VERSION ""

NS_ :

BS_:

BU_: Display PERS PCU_LMX MIC_id10 MIC_id20 Battery
VAL_TABLE_ VESC_Fault_Code 29 "LV_OUTPUT_FAULT" 28 "ENCODER_FAULT" 27 "PHASE_FILTER" 26 "ENCODER_MAGNET_TOO_STRONG" 25 "ENCODER_NO_MAGNET" 24 "FLASH_CORRUPTION_MC_CFG" 23 "FLASH_CORRUPTION_APP_CFG" 22 "RESOLVER_LOS" 21 "RESOLVER_DOS" 20 "RESOLVER_LOT" 19 "BRK" 18 "UNBALANCED_CURRENTS" 17 "HIGH_OFFSET_CURRENT_SENSOR_3" 16 "HIGH_OFFSET_CURRENT_SENSOR_2" 15 "HIGH_OFFSET_CURRENT_SENSOR_1" 14 "FLASH_CORRUPTION" 13 "ENCODER_SINCOS_MAX_AMPLITUDE" 12 "ENCODER_SINCOS_MIN_AMPLITUDE" 11 "ENCODER_SPI" 10 "BOOTING_FROM_WATCHDOG_RESET" 9 "MCU_UNDER_VOLTAGE" 8 "GATE_DRIVER_UNDER_VOLTAGE" 7 "GATE_DRIVER_OVER_VOLTAGE" 6 "OVER_TEMP_MOTOR" 5 "OVER_TEMP_FET" 4 "ABS_OVER_CURRENT" 3 "DRV" 2 "UNDER_VOLTAGE" 1 "OVER_VOLTAGE" 0 "NONE" ;
VAL_TABLE_ BMS_State 120 "REGEN" 110 "DISCHARGING" 100 "IDLE" 90 "OVERVOLTAGE" 70 "STANDBY" 40 "UNDERVOLTAGE" 30 "PROTECT" 20 "INIT" 10 "ERROR" ;

BO_ 3221225472 VECTOR__INDEPENDENT_SIG_MSG: 0 Vector__XXX
 SG_ Set_DutyCycle : 0|16@0- (1E-05,0) [-1|1] "%/100" Vector__XXX
 SG_ Set_DutyCycle : 0|16@0- (1E-05,0) [-1|1] "%/100" Vector__XXX

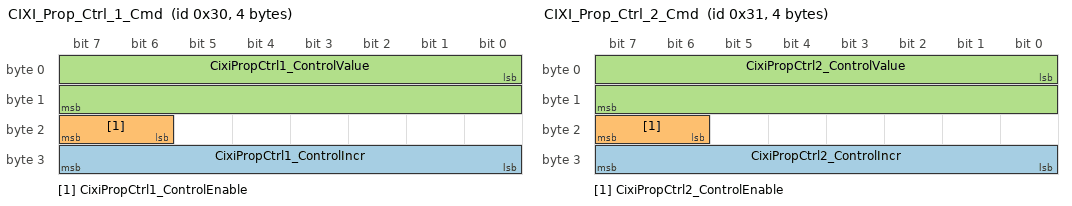
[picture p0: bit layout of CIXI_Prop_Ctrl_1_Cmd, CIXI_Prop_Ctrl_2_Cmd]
BO_ 48 CIXI_Prop_Ctrl_1_Cmd: 4 PERS
 SG_ CixiPropCtrl1_ControlIncr : 24|8@1+ (1,0) [0|255] "-"  PCU_LMX
 SG_ CixiPropCtrl1_ControlEnable : 22|2@1+ (1,0) [0|3] ""  PCU_LMX
 SG_ CixiPropCtrl1_ControlValue : 0|16@1- (0.1,0) [-3276|3276] "N.m"  PCU_LMX

BO_ 49 CIXI_Prop_Ctrl_2_Cmd: 4 PERS
 SG_ CixiPropCtrl2_ControlIncr : 24|8@1+ (1,0) [0|255] "-"  PCU_LMX
 SG_ CixiPropCtrl2_ControlEnable : 22|2@1+ (1,0) [0|3] ""  PCU_LMX
 SG_ CixiPropCtrl2_ControlValue : 0|16@1- (0.1,0) [-3276|3276] "N.m"  PCU_LMX

BO_ 56 CIXI_Prop_Ctrl_1_Status: 7 PCU_LMX
 SG_ CixiPropCtrl1_Iq m2 : 40|16@1- (0.01,0) [-327|327] "A"  PERS
 SG_ CixiPropCtrl1_MotorRpmSensless m1 : 40|16@1- (0.1,0) [-3276|3276] "RPM"  PERS
 SG_ CixiPropCtrl1_MotorRpmSensored m0 : 40|16@1- (0.1,0) [-3276|3276] "RPM"  PERS
 SG_ CixiPropCtrl1_InputCurrent m2 : 24|16@1- (0.01,0) [-327|327] "A"  PERS
 SG_ CixiPropCtrl1_MechanicalPower m1 : 24|16@1- (1,0) [-32768|32767] "W"  PERS
 SG_ CixiPropCtrl1_MotorTorque m0 : 24|16@1- (0.1,0) [-3276|3276] "N.m"  PERS
 SG_ CixiPropCtrl1_InputVoltage m2 : 8|16@1+ (0.01,0) [0|655] "V"  PERS
 SG_ CixiPropCtrl1_ElectricalPower m1 : 8|16@1- (1,0) [-32768|32767] "W"  PERS
 SG_ CixiPropCtrl1_ControlValueIn m0 : 8|16@1- (0.1,0) [-3276|3276] "N.m"  PERS
 SG_ CixiPropCtrl1_ControlState : 6|2@1+ (1,0) [0|3] ""  PERS
 SG_ CixiPropCtrl1_StatusNbPage : 2|2@1+ (1,0) [0|3] ""  PERS
 SG_ CixiPropCtrl1_StatusPage M : 0|2@1+ (1,0) [0|3] ""  PERS

BO_ 57 CIXI_Prop_Ctrl_2_Status: 7 PCU_LMX
 SG_ CixiPropCtrl2_Iq m2 : 40|16@1- (0.01,0) [-327|327] "A"  PERS
 SG_ CixiPropCtrl2_MotorRpmSensless m1 : 40|16@1- (0.1,0) [-3276|3276] "RPM"  PERS
 SG_ CixiPropCtrl2_MotorRpmSensored m0 : 40|16@1- (0.1,0) [-3276|3276] "RPM"  PERS
 SG_ CixiPropCtrl2_InputCurrent m2 : 24|16@1- (0.01,0) [-327|327] "A"  PERS
 SG_ CixiPropCtrl2_MechanicalPower m1 : 24|16@1- (1,0) [-32768|32767] "W"  PERS
 SG_ CixiPropCtrl2_MotorTorque m0 : 24|16@1- (0.1,0) [-3276|3276] "N.m"  PERS
 SG_ CixiPropCtrl2_InputVoltage m2 : 8|16@1+ (0.01,0) [0|655] "V"  PERS
 SG_ CixiPropCtrl2_ElectricalPower m1 : 8|16@1- (1,0) [-32768|32767] "W"  PERS
 SG_ CixiPropCtrl2_ControlValueIn m0 : 8|16@1- (0.1,0) [-3276|3276] "N.m"  PERS
 SG_ CixiPropCtrl2_ControlState : 6|2@1+ (1,0) [0|3] ""  PERS
 SG_ CixiPropCtrl2_StatusNbPage : 2|2@1+ (1,0) [0|3] ""  PERS
 SG_ CixiPropCtrl2_StatusPage M : 0|2@1+ (1,0) [0|3] ""  PERS

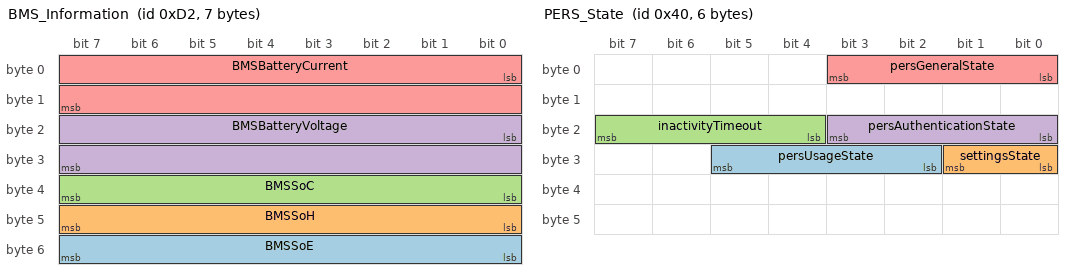
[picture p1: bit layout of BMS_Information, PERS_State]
BO_ 210 BMS_Information: 7 PCU_LMX
 SG_ BMSSoE : 48|8@1- (1,0) [0|100] "%"  PERS
 SG_ BMSSoH : 40|8@1- (1,0) [0|100] "%"  PERS
 SG_ BMSSoC : 32|8@1- (1,0) [0|100] "%"  PERS
 SG_ BMSBatteryVoltage : 16|16@1- (0.01,0) [0|655] "V"  PERS
 SG_ BMSBatteryCurrent : 0|16@1- (0.01,0) [-327|327] "A"  PERS

BO_ 64 PERS_State: 6 PERS
 SG_ persUsageState : 26|4@1+ (1,0) [0|15] "-" Vector__XXX
 SG_ settingsState : 24|2@1+ (1,0) [0|3] "-" Vector__XXX
 SG_ inactivityTimeout : 20|4@1+ (1,0) [0|15] "sec" Vector__XXX
 SG_ persAuthenticationState : 16|4@1+ (1,0) [0|15] "" Vector__XXX
 SG_ persGeneralState : 0|4@1+ (1,0) [0|15] "" Vector__XXX

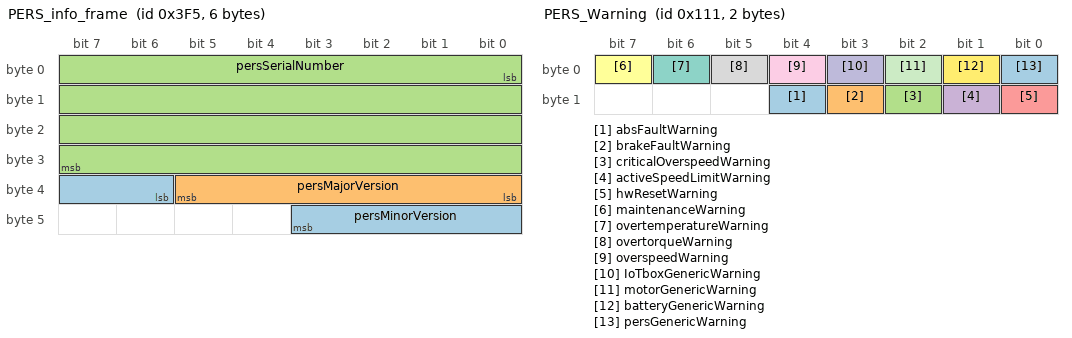
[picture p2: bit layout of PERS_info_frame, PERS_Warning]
BO_ 1013 PERS_info_frame: 6 PERS
 SG_ persMinorVersion : 38|6@1+ (1,0) [0|63] "-" Vector__XXX
 SG_ persMajorVersion : 32|6@1+ (1,0) [0|63] "-" Vector__XXX
 SG_ persSerialNumber : 0|32@1+ (1,0) [0|4294967295] "-" Vector__XXX

BO_ 273 PERS_Warning: 2 PERS
 SG_ absFaultWarning : 12|1@1+ (1,0) [0|1] "-" Vector__XXX
 SG_ brakeFaultWarning : 11|1@1+ (1,0) [0|1] "-" Vector__XXX
 SG_ criticalOverspeedWarning : 10|1@1+ (1,0) [0|1] "-" Vector__XXX
 SG_ activeSpeedLimitWarning : 9|1@1+ (1,0) [0|1] "-" Vector__XXX
 SG_ hwResetWarning : 8|1@1+ (1,0) [0|1] "-" Vector__XXX
 SG_ maintenanceWarning : 7|1@1+ (1,0) [0|1] "-" Vector__XXX
 SG_ overtemperatureWarning : 6|1@1+ (1,0) [0|1] "-" Vector__XXX
 SG_ overtorqueWarning : 5|1@1+ (1,0) [0|1] "" Vector__XXX
 SG_ overspeedWarning : 4|1@1+ (1,0) [0|1] "-" Vector__XXX
 SG_ IoTboxGenericWarning : 3|1@1+ (1,0) [0|1] "-" Vector__XXX
 SG_ motorGenericWarning : 2|1@1+ (1,0) [0|1] "-" Vector__XXX
 SG_ batteryGenericWarning : 1|1@1+ (1,0) [0|1] "-" Vector__XXX
 SG_ persGenericWarning : 0|1@1+ (1,0) [0|1] "-" Vector__XXX

BO_ 272 PERS_Error: 1 PERS
 SG_ persGenericError : 0|1@1+ (1,0) [0|1] "-" Vector__XXX

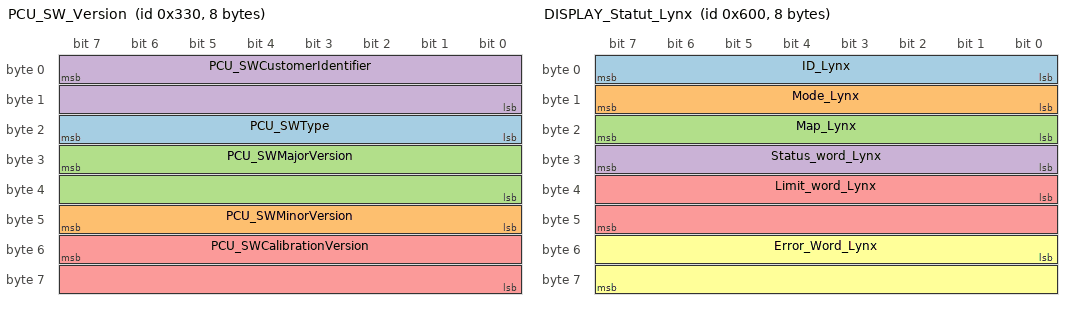
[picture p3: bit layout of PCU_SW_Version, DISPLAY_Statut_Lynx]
BO_ 816 PCU_SW_Version: 8 PCU_LMX
 SG_ PCU_SWType : 23|8@0+ (1,0) [0|0] "" Vector__XXX
 SG_ PCU_SWMinorVersion : 47|8@0+ (1,0) [0|0] "" Vector__XXX
 SG_ PCU_SWMajorVersion : 31|16@0+ (1,0) [0|0] "" Vector__XXX
 SG_ PCU_SWCustomerIdentifier : 7|16@0+ (1,0) [0|0] "" Vector__XXX
 SG_ PCU_SWCalibrationVersion : 55|16@0+ (1,0) [0|0] "" Vector__XXX

BO_ 1536 DISPLAY_Statut_Lynx: 8 PCU_LMX
 SG_ ID_Lynx : 0|8@1+ (1,0) [0|0] ""  Display
 SG_ Mode_Lynx : 8|8@1+ (1,0) [0|0] ""  Display
 SG_ Map_Lynx : 16|8@1+ (1,0) [0|0] ""  Display
 SG_ Status_word_Lynx : 24|8@1+ (1,0) [0|0] ""  Display
 SG_ Limit_word_Lynx : 32|16@1+ (1,0) [0|0] ""  Display
 SG_ Error_Word_Lynx : 48|16@1+ (1,0) [0|0] ""  Display

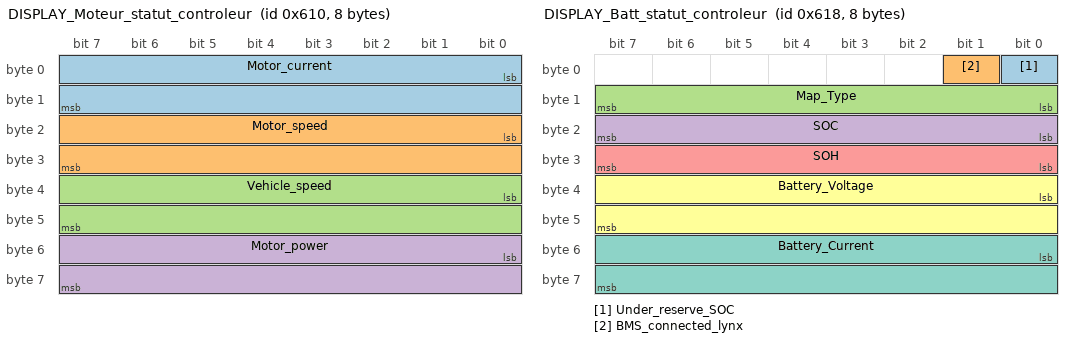
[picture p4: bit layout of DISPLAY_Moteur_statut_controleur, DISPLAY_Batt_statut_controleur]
BO_ 1552 DISPLAY_Moteur_statut_controleur: 8 PCU_LMX
 SG_ Motor_current : 0|16@1- (1,0) [-32768|32767] "A"  Display
 SG_ Motor_speed : 16|16@1- (1,0) [-32768|32767] "RPM"  Display
 SG_ Vehicle_speed : 32|16@1- (0.01,0) [0|0] "km/h"  Display
 SG_ Motor_power : 48|16@1- (1,0) [0|0] "W"  Display

BO_ 1560 DISPLAY_Batt_statut_controleur: 8 PCU_LMX
 SG_ Under_reserve_SOC : 0|1@1+ (1,0) [0|0] ""  Display
 SG_ BMS_connected_lynx : 1|1@1+ (1,0) [0|0] ""  Display
 SG_ Map_Type : 8|8@1+ (1,0) [0|0] ""  Display
 SG_ SOC : 16|8@1+ (1,0) [0|100] "%"  Display
 SG_ SOH : 24|8@1+ (1,0) [0|0] "%"  Display
 SG_ Battery_Voltage : 32|16@1- (0.01,0) [-327.68|327.67] "V"  Display
 SG_ Battery_Current : 48|16@1- (0.02,0) [-655.36|655.34] "A"  Display

BO_ 1568 DISPLAY_Odo_trip_controleur: 8 PCU_LMX
 SG_ Trip : 0|32@1+ (0.01,0) [0|0] "km"  Display
 SG_ Odometer : 32|32@1+ (0.1,0) [0|0] "km"  Display

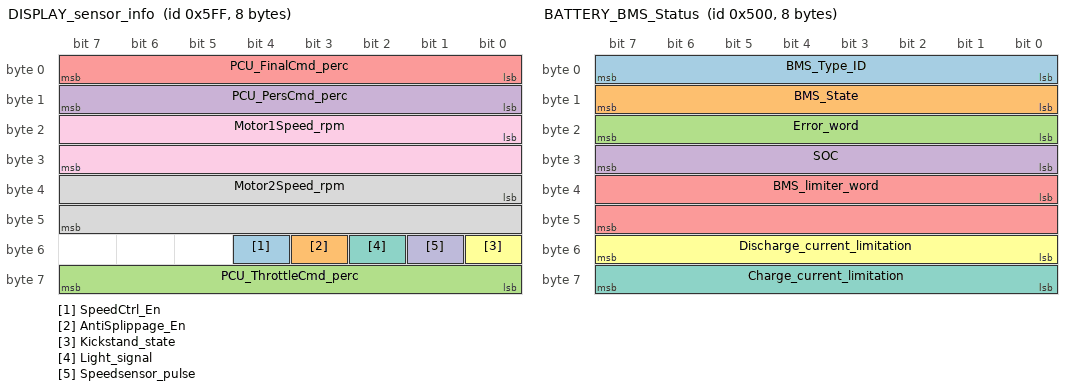
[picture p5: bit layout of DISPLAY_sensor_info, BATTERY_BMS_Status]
BO_ 1535 DISPLAY_sensor_info: 8 PCU_LMX
 SG_ SpeedCtrl_En : 52|1@1- (1,0) [0|0] "" Vector__XXX
 SG_ AntiSplippage_En : 51|1@1- (1,0) [0|0] "" Vector__XXX
 SG_ PCU_ThrottleCmd_perc : 56|8@1+ (1,-100) [-100|100] "%" Vector__XXX
 SG_ PCU_PersCmd_perc : 8|8@1+ (1,-100) [-100|100] "%" Vector__XXX
 SG_ PCU_FinalCmd_perc : 0|8@1+ (1,-100) [-100|100] "%" Vector__XXX
 SG_ Kickstand_state : 48|1@1+ (1,0) [0|0] "" Vector__XXX
 SG_ Light_signal : 50|1@1+ (1,0) [0|0] "" Vector__XXX
 SG_ Motor2Speed_rpm : 32|16@1- (1,0) [-32768|32767] "RPM" Vector__XXX
 SG_ Motor1Speed_rpm : 16|16@1- (1,0) [-32768|32767] "RPM" Vector__XXX
 SG_ Speedsensor_pulse : 49|1@1+ (1,0) [0|0] ""  Display

BO_ 1280 BATTERY_BMS_Status: 8 Battery
 SG_ BMS_Type_ID : 0|8@1+ (1,0) [-3276.8|3276.7] ""  PCU_LMX
 SG_ BMS_State : 8|8@1+ (1,0) [-3276.8|3276.7] ""  PCU_LMX
 SG_ Error_word : 16|8@1+ (0.1,0) [-3276.8|3276.7] ""  PCU_LMX
 SG_ SOC : 24|8@1+ (0.5,0) [0|200] "%"  PCU_LMX
 SG_ BMS_limiter_word : 32|16@1+ (1,0) [-32768|32767] ""  PCU_LMX
 SG_ Discharge_current_limitation : 48|8@1+ (1,0) [0|255] "%"  PCU_LMX
 SG_ Charge_current_limitation : 56|8@1+ (1,0) [0|255] "%"  PCU_LMX

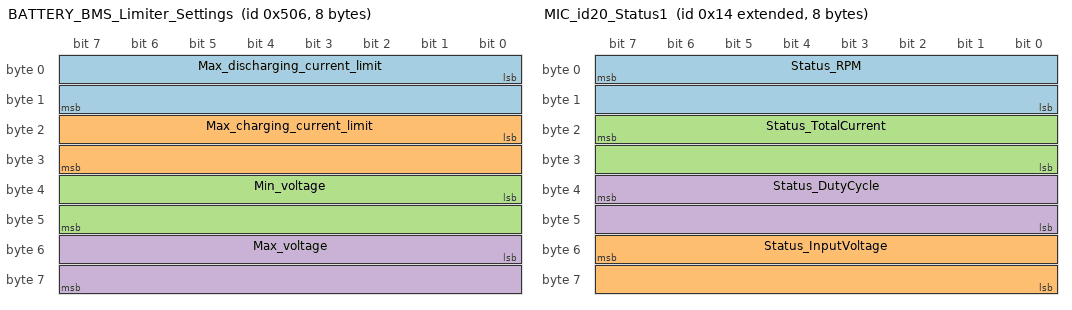
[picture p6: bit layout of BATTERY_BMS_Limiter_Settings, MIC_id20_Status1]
BO_ 1286 BATTERY_BMS_Limiter_Settings: 8 Battery
 SG_ Max_discharging_current_limit : 0|16@1- (0.1,0) [-3276.8|3276.7] "A"  PCU_LMX
 SG_ Max_charging_current_limit : 16|16@1- (0.1,0) [-3276.8|3276.7] "A"  PCU_LMX
 SG_ Min_voltage : 32|16@1- (0.1,0) [-3276.8|3276.7] "V"  PCU_LMX
 SG_ Max_voltage : 48|16@1- (0.1,0) [-3276.8|3276.7] "V"  PCU_LMX

BO_ 2147489556 MIC_id20_Set_InputCurrent_Limits: 8 PCU_LMX
 SG_ Set_Min_Input_Current_Limit : 7|32@0- (0.001,0) [-2147483.648|0] "A"  MIC_id20
 SG_ Set_Max_Input_Current_Limit : 39|32@0- (0.001,0) [0|2147483.647] "A"  MIC_id20

BO_ 2147489546 MIC_id10_Set_InputCurrent_Limits: 8 PCU_LMX
 SG_ Set_Min_Input_Current_Limit : 7|32@0- (0.001,0) [-2147483.648|0] "A"  MIC_id20
 SG_ Set_Max_Input_Current_Limit : 39|32@0- (0.001,0) [0|2147483.647] "A"  MIC_id20

BO_ 2147489044 MIC_id20_Set_Current_Limits: 8 PCU_LMX
 SG_ Set_Min_Current_Limit : 7|32@0- (0.001,0) [-2147483.648|0] "Arms"  MIC_id20
 SG_ Set_Max_Current_Limit : 39|32@0- (0.001,0) [0|2147483.647] "Arms"  MIC_id20

BO_ 2147489034 MIC_id10_Set_Current_Limits: 8 PCU_LMX
 SG_ Set_Min_Current_Limit : 7|32@0- (0.001,0) [-2147483.648|0] "Arms"  MIC_id20
 SG_ Set_Max_Current_Limit : 39|32@0- (0.001,0) [0|2147483.647] "Arms"  MIC_id20

BO_ 2147484180 MIC_id20_Set_Current_Brake: 4 PCU_LMX
 SG_ Set_Current_Brake : 7|32@0- (0.001,0) [-2147483.648|2147483.647] "Arms"  MIC_id20

BO_ 2147484170 MIC_id10_Set_Current_Brake: 4 PCU_LMX
 SG_ Set_Current_Brake : 7|32@0- (0.001,0) [-2147483.648|2147483.647] "Arms"  MIC_id20

BO_ 2147483924 MIC_id20_Set_Current: 4 PCU_LMX
 SG_ Set_Current : 7|32@0- (0.001,0) [-2147483.648|2147483.647] "Arms"  MIC_id20

BO_ 2147483914 MIC_id10_Set_Current: 4 PCU_LMX
 SG_ Set_Current : 7|32@0- (0.001,0) [-2147483.648|2147483.647] "Arms"  MIC_id20

BO_ 2147485706 MIC_id10_Send_Command: 7 PCU_LMX
 SG_ Value : 31|32@0- (0.001,0) [-32768|32767] ""  MIC_id20
 SG_ mode : 23|8@0+ (1,0) [0|0] ""  MIC_id20

BO_ 2147485716 MIC_id20_Send_Command: 7 PCU_LMX
 SG_ mode : 23|8@0+ (1,0) [0|0] ""  MIC_id20,MIC_id10
 SG_ Value : 31|32@0- (0.001,0) [-32768|32767] ""  MIC_id20,MIC_id10

BO_ 2147483668 MIC_id20_Status1: 8 MIC_id20
 SG_ Status_RPM : 7|16@0- (2,0) [-6553.6|6553.4] "RPM" Vector__XXX
 SG_ Status_InputVoltage : 55|16@0- (0.1,0) [-3276.8|3276.7] "V" Vector__XXX
 SG_ Status_TotalCurrent : 23|16@0- (0.1,0) [-3276.8|3276.7] "ARMS"  PCU_LMX
 SG_ Status_DutyCycle : 39|16@0- (0.1,0) [-100|100] "%"  PCU_LMX

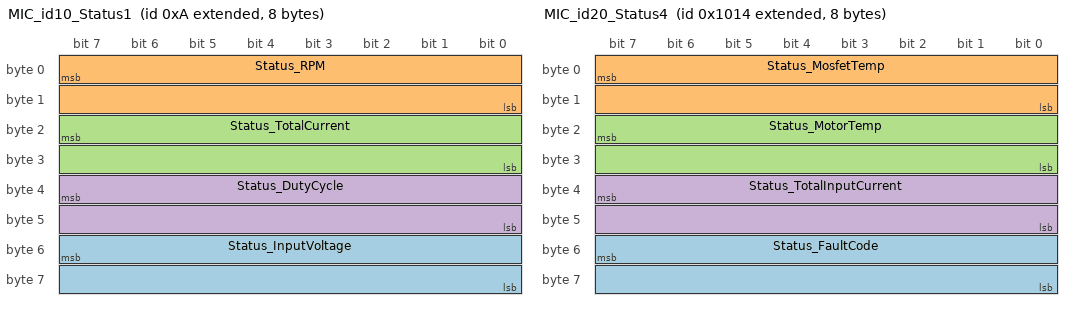
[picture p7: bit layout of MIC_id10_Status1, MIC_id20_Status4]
BO_ 2147483658 MIC_id10_Status1: 8 MIC_id10
 SG_ Status_InputVoltage : 55|16@0- (0.1,0) [-3276.8|3276.7] "V" Vector__XXX
 SG_ Status_RPM : 7|16@0- (2,0) [-6553.6|6553.4] "RPM"  PCU_LMX
 SG_ Status_TotalCurrent : 23|16@0- (0.1,0) [-327.68|327.67] "ARMS"  PCU_LMX
 SG_ Status_DutyCycle : 39|16@0- (0.1,0) [-3276.8|3276.7] "%"  PCU_LMX

BO_ 2147487252 MIC_id20_Status2: 8 MIC_id20
 SG_ Status_Iq : 39|32@0- (0.001,0) [-214748.3648|214748.3647] "A" Vector__XXX
 SG_ Status_Id : 7|32@0- (0.001,0) [-214748364.8|214748364.7] "A" Vector__XXX

BO_ 2147487242 MIC_id10_Status2: 8 MIC_id10
 SG_ Status_Id : 7|32@0- (0.001,0) [-21474836.48|21474836.47] "A"  PCU_LMX
 SG_ Status_Iq : 39|32@0- (0.001,0) [-2147483.648|2147483.647] "A"  PCU_LMX

BO_ 2147487508 MIC_id20_Status3: 8 MIC_id20
 SG_ Status_WattHoursCharged : 39|32@0- (1E-05,0) [-21474.83648|21474.83647] "Wh"  PCU_LMX
 SG_ Status_WattHours : 7|32@0- (1E-05,0) [-21474.83648|21474.83647] "Wh"  PCU_LMX

BO_ 2147487498 MIC_id10_Status3: 8 MIC_id10
 SG_ Status_WattHours : 7|32@0- (0.0001,0) [-21474.83648|21474.83647] "Wh"  PCU_LMX
 SG_ Status_WattHoursCharged : 39|32@0- (0.0001,0) [-21474.83648|21474.83647] "Wh"  PCU_LMX

BO_ 2147487764 MIC_id20_Status4: 8 MIC_id20
 SG_ Status_FaultCode : 55|16@0+ (1,0) [0|65535] "" Vector__XXX
 SG_ Status_MosfetTemp : 7|16@0- (0.1,0) [-3276.8|3276.7] "degC"  PCU_LMX
 SG_ Status_MotorTemp : 23|16@0- (0.1,0) [-3276.8|3276.7] "degC"  PCU_LMX
 SG_ Status_TotalInputCurrent : 39|16@0- (0.1,0) [-3276.8|3276.7] "A"  PCU_LMX

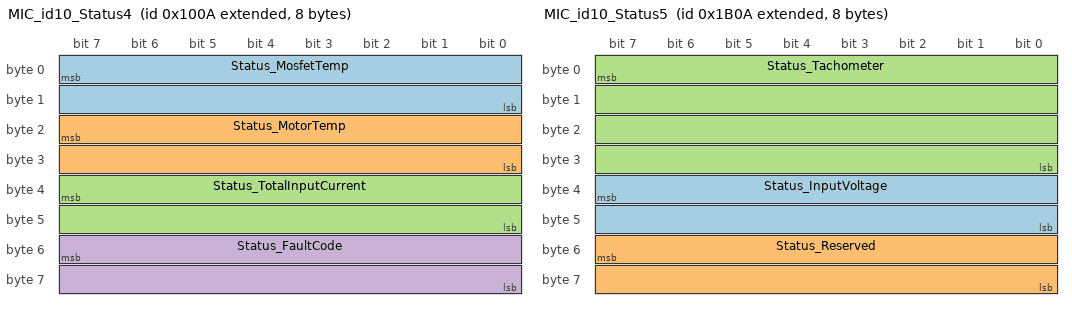
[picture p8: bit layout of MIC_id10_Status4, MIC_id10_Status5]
BO_ 2147487754 MIC_id10_Status4: 8 MIC_id10
 SG_ Status_MosfetTemp : 7|16@0- (0.1,0) [-3276.8|3276.7] "degC"  PCU_LMX
 SG_ Status_MotorTemp : 23|16@0- (0.1,0) [-3276.8|3276.7] "degC"  PCU_LMX
 SG_ Status_TotalInputCurrent : 39|16@0- (0.1,0) [-3276.8|3276.7] "A"  PCU_LMX
 SG_ Status_FaultCode : 55|16@0+ (1,0) [0|65535] ""  PCU_LMX

BO_ 2147490580 MIC_id20_Status5: 8 MIC_id20
 SG_ Status_Reserved : 55|16@0- (1,0) [0|0] ""  PCU_LMX
 SG_ Status_Tachometer : 7|32@0- (1,0) [0|0] "RPM"  PCU_LMX

BO_ 2147490570 MIC_id10_Status5: 8 MIC_id10
 SG_ Status_InputVoltage : 39|16@0- (0.1,0) [-3276.8|3276.7] "V"  PCU_LMX
 SG_ Status_Reserved : 55|16@0- (1,0) [0|0] ""  PCU_LMX
 SG_ Status_Tachometer : 7|32@0- (1,0) [0|0] "RPM"  PCU_LMX

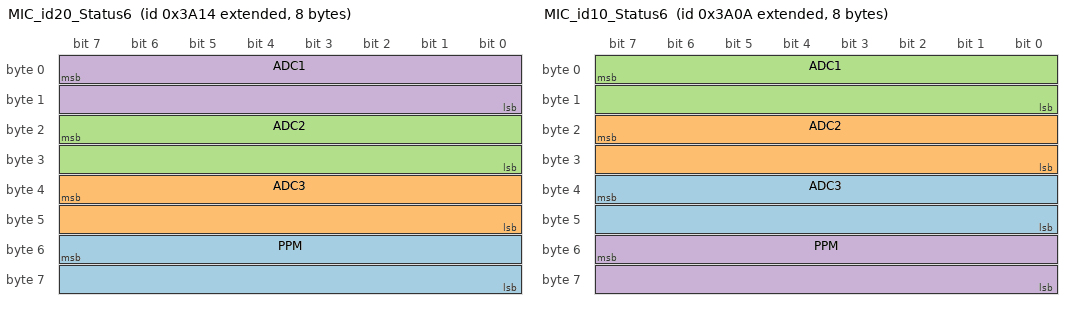
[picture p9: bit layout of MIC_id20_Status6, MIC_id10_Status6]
BO_ 2147498516 MIC_id20_Status6: 8 MIC_id20
 SG_ PPM : 55|16@0+ (1000,0) [0|0] "%"  PCU_LMX
 SG_ ADC3 : 39|16@0+ (0.001,0) [0|0] "V"  PCU_LMX
 SG_ ADC2 : 23|16@0+ (0.001,0) [0|0] "V"  PCU_LMX
 SG_ ADC1 : 7|16@0+ (0.001,0) [0|0] "V"  PCU_LMX

BO_ 2147498506 MIC_id10_Status6: 8 MIC_id10
 SG_ ADC3 : 39|16@0+ (0.001,0) [0|0] "V" Vector__XXX
 SG_ ADC2 : 23|16@0+ (0.001,0) [0|0] "V" Vector__XXX
 SG_ ADC1 : 7|16@0+ (0.001,0) [0|0] "V" Vector__XXX
 SG_ PPM : 55|16@0+ (1000,0) [0|0] "%"  PCU_LMX

CM_ BU_ PCU_LMX "
";
CM_ BO_ 3221225472 "This is a message for not used signals, created by Vector CANdb++ DBC OLE DB Provider.";
CM_ SG_ 48 CixiPropCtrl1_ControlIncr "Incremental value to be sure that command is not frozen.";
CM_ SG_ 48 CixiPropCtrl1_ControlEnable "The \"CixiPropCtrlControlValue\" shall be take into account only if ENABLE=3DACTIVE";
CM_ SG_ 48 CixiPropCtrl1_ControlValue "Torque setpoint to apply";
CM_ SG_ 49 CixiPropCtrl2_ControlIncr "Incremental value to be sure that command is not frozen.";
CM_ SG_ 49 CixiPropCtrl2_ControlEnable "The \"CixiPropCtrlControlValue\" shall be take into account only if ENABLE=3DACTIVE";
CM_ SG_ 49 CixiPropCtrl2_ControlValue "Torque setpoint to apply";
CM_ SG_ 210 BMSSoC "Battery state of Charge";
CM_ SG_ 273 criticalOverspeedWarning "vehicle critical overspeed warning";
CM_ SG_ 273 activeSpeedLimitWarning "Active speed limit unavailable";
CM_ SG_ 273 hwResetWarning "PERS HW reset trigger warning";
CM_ SG_ 273 maintenanceWarning "Mid-life maintenance warning";
CM_ SG_ 273 overtemperatureWarning "System is too hot";
CM_ SG_ 273 overspeedWarning "Vehicle overspeed warning";
CM_ BO_ 1536 "100 ms";
CM_ BO_ 1552 "100 ms";
CM_ BO_ 1560 "100 ms";
CM_ SG_ 1560 SOC "Battery Sate of Charge";
CM_ SG_ 1560 Battery_Voltage "Battery voltage";
CM_ SG_ 1560 Battery_Current "Battery current";
CM_ BO_ 1568 "100 ms";
CM_ BO_ 1535 "50 ms";
CM_ SG_ 1280 BMS_Type_ID "ID of the BMS type (expected 0xF0)";
CM_ SG_ 1280 BMS_State "BMS status";
CM_ SG_ 1280 Error_word "Not Used";
CM_ SG_ 1280 SOC "Battery State of Charge";
CM_ SG_ 1280 BMS_limiter_word "Not Used";
CM_ SG_ 1280 Discharge_current_limitation "Dynamic discharge derating
Max discharge current available (%) = round(RAW_Val * (255 /100))";
CM_ SG_ 1280 Charge_current_limitation "Dynamic regen derating
Max charge current available (%) = round(RAW_Val * (255 /100))";
BA_DEF_ BO_  "VFrameFormat" ENUM  "StandardCAN","ExtendedCAN","reserved","reserved","reserved","reserved","reserved","reserved","reserved","reserved","reserved","reserved","reserved","reserved","StandardCAN_FD","ExtendedCAN_FD";
BA_DEF_ BO_  "CANFD_BRS" ENUM  "0","1";
BA_DEF_  "BusType" STRING ;
BA_DEF_ SG_  "GenSigStartValue" FLOAT -3.4E+38 3.4E+38;
BA_DEF_DEF_  "VFrameFormat" "";
BA_DEF_DEF_  "CANFD_BRS" "1";
BA_DEF_DEF_  "BusType" "CAN";
BA_DEF_DEF_  "GenSigStartValue" 0;
BA_ "VFrameFormat" BO_ 56 0;
BA_ "VFrameFormat" BO_ 57 0;
BA_ "VFrameFormat" BO_ 210 0;
BA_ "VFrameFormat" BO_ 816 0;
BA_ "VFrameFormat" BO_ 1535 0;
BA_ "VFrameFormat" BO_ 2147483668 1;
BA_ "VFrameFormat" BO_ 2147483658 1;
BA_ "VFrameFormat" BO_ 2147487252 1;
BA_ "VFrameFormat" BO_ 2147487764 1;
BA_ "VFrameFormat" BO_ 2147498506 1;
BA_ "GenSigStartValue" SG_ 1535 PCU_ThrottleCmd_perc 100;
BA_ "GenSigStartValue" SG_ 1535 PCU_PersCmd_perc 100;
BA_ "GenSigStartValue" SG_ 1535 PCU_FinalCmd_perc 100;
VAL_ 48 CixiPropCtrl1_ControlEnable 0 "STANDBY" 3 "ACTIVE" ;
VAL_ 49 CixiPropCtrl2_ControlEnable 0 "STANDBY" 3 "ACTIVE" ;
VAL_ 56 CixiPropCtrl1_ControlState 0 "INIT" 1 "STANDBY" 2 "ACTIVE" 3 "ERROR" ;
VAL_ 57 CixiPropCtrl2_ControlState 0 "INIT" 1 "STANDBY" 2 "ACTIVE" 3 "ERROR" ;
VAL_ 64 persUsageState 0 "PERS_NORMAL" 1 "PERS_ALARM" 2 "PERS_LOST" 3 "PERS_NEUTRALIZED" ;
VAL_ 64 settingsState 0 "NOT_AVAILABLE" 3 "AVAILABLE" ;
VAL_ 64 persAuthenticationState 0 "PERS_UNAUTHENTIFIED" 1 "PERS_AUTHENTIFICATION_FAIL" 2 "PERS_AUTHENTIFIED" 3 "PERS_AUTHENTICATION_LOCKED" ;
VAL_ 64 persGeneralState 0 "PERS_OFF" 1 "PERS_PREP" 2 "PERS_NEUTRAL" 10 "PERS_ACTIVE_DRIVING" ;
VAL_ 273 absFaultWarning 0 "NOT_ACTIVE" 1 "ACTIVE" ;
VAL_ 273 brakeFaultWarning 0 "NOT_ACTIVE" 1 "ACTIVE" ;
VAL_ 273 criticalOverspeedWarning 0 "NOT_ACTIVE" 1 "ACTIVE" ;
VAL_ 273 activeSpeedLimitWarning 0 "NOT_ACTIVE" 1 "ACTIVE" ;
VAL_ 273 hwResetWarning 0 "NOT_ACTIVE" 1 "ACTIVE" ;
VAL_ 273 maintenanceWarning 0 "NOT_ACTIVE" 1 "ACTIVE" ;
VAL_ 273 overtemperatureWarning 0 "NOT_ACTIVE" 1 "ACTIVE" ;
VAL_ 273 overtorqueWarning 0 "NOT_ACTIVE" 1 "ACTIVE" ;
VAL_ 273 overspeedWarning 0 "NOT_ACTIVE" 1 "ACTIVE" ;
VAL_ 273 IoTboxGenericWarning 0 "NOT_ACTIVE" 1 "ACTIVE" ;
VAL_ 273 motorGenericWarning 0 "NOT_ACTIVE" 1 "ACTIVE" ;
VAL_ 273 batteryGenericWarning 0 "NOT_ACTIVE" 1 "ACTIVE" ;
VAL_ 273 persGenericWarning 0 "NOT_ACTIVE" 1 "ACTIVE" ;
VAL_ 272 persGenericError 0 "NOT_ACTIVE" 1 "ACTIVE" ;
VAL_ 1280 BMS_State 120 "REGEN" 110 "DISCHARGING" 100 "IDLE" 90 "OVERVOLTAGE" 70 "STANDBY" 40 "UNDERVOLTAGE" 30 "PROTECT" 20 "INIT" 10 "ERROR" ;
VAL_ 2147487764 Status_FaultCode 29 "LV_OUTPUT_FAULT" 28 "ENCODER_FAULT" 27 "PHASE_FILTER" 26 "ENCODER_MAGNET_TOO_STRONG" 25 "ENCODER_NO_MAGNET" 24 "FLASH_CORRUPTION_MC_CFG" 23 "FLASH_CORRUPTION_APP_CFG" 22 "RESOLVER_LOS" 21 "RESOLVER_DOS" 20 "RESOLVER_LOT" 19 "BRK" 18 "UNBALANCED_CURRENTS" 17 "HIGH_OFFSET_CURRENT_SENSOR_3" 16 "HIGH_OFFSET_CURRENT_SENSOR_2" 15 "HIGH_OFFSET_CURRENT_SENSOR_1" 14 "FLASH_CORRUPTION" 13 "ENCODER_SINCOS_MAX_AMPLITUDE" 12 "ENCODER_SINCOS_MIN_AMPLITUDE" 11 "ENCODER_SPI" 10 "BOOTING_FROM_WATCHDOG_RESET" 9 "MCU_UNDER_VOLTAGE" 8 "GATE_DRIVER_UNDER_VOLTAGE" 7 "GATE_DRIVER_OVER_VOLTAGE" 6 "OVER_TEMP_MOTOR" 5 "OVER_TEMP_FET" 4 "ABS_OVER_CURRENT" 3 "DRV" 2 "UNDER_VOLTAGE" 1 "OVER_VOLTAGE" 0 "NONE" ;
VAL_ 2147487754 Status_FaultCode 29 "LV_OUTPUT_FAULT" 28 "ENCODER_FAULT" 27 "PHASE_FILTER" 26 "ENCODER_MAGNET_TOO_STRONG" 25 "ENCODER_NO_MAGNET" 24 "FLASH_CORRUPTION_MC_CFG" 23 "FLASH_CORRUPTION_APP_CFG" 22 "RESOLVER_LOS" 21 "RESOLVER_DOS" 20 "RESOLVER_LOT" 19 "BRK" 18 "UNBALANCED_CURRENTS" 17 "HIGH_OFFSET_CURRENT_SENSOR_3" 16 "HIGH_OFFSET_CURRENT_SENSOR_2" 15 "HIGH_OFFSET_CURRENT_SENSOR_1" 14 "FLASH_CORRUPTION" 13 "ENCODER_SINCOS_MAX_AMPLITUDE" 12 "ENCODER_SINCOS_MIN_AMPLITUDE" 11 "ENCODER_SPI" 10 "BOOTING_FROM_WATCHDOG_RESET" 9 "MCU_UNDER_VOLTAGE" 8 "GATE_DRIVER_UNDER_VOLTAGE" 7 "GATE_DRIVER_OVER_VOLTAGE" 6 "OVER_TEMP_MOTOR" 5 "OVER_TEMP_FET" 4 "ABS_OVER_CURRENT" 3 "DRV" 2 "UNDER_VOLTAGE" 1 "OVER_VOLTAGE" 0 "NONE" ;
